# FE310 register map
Vendor: SiFive; Series: Freedom Everywhere; File version: v19p05
E31 CPU Coreplex, high-performance, 32-bit RV32IMAC core
CPU: E31 rv32imac, little endian, no MPU, no FPU, vendor SysTick, 1 interrupt priority bits
Registers are 32-bit, read-write, reset 0x0 unless marked. A register's access mark holds for its fields unless they carry their own. Offsets are from the block's base; lines under a group give offsets from that group; [hi:lo] are bit positions; {n}, {i} and the like mark numbered series; 'fields as' and 'values as' point back to an identical list; <NAME> marks a mode.

## Memory map
0x00020000 OTP_Mem size 0x2000 — One-Time Programmable Memory.
0x02000000 CLINT size 0x10000 — Core Local Interruptor.
0x0C000000 PLIC size 0x200008 — Platform-Level Interrupt Controller.
0x10000000 WDT size 0x40 — Watchdog Timer.
0x10000040 RTC size 0x30 — Real-Time Clock.
0x10000070 AON size 0x10 — AON Clock Configuration.
0x10000080 BACKUP size 0x80 — Backup Registers.
0x10000100 PMU size 0x50 — Power Management Unit.
0x10008000 PRIC size 0x10 — Power, Reset, Clock, Interrupt.
0x10012000 GPIO0 size 0x1000 — General purpose input/output controller.
0x10013000 UART0 size 0x1000 — Universal Asynchronous Receiver/Transmitter.
0x10014000 QSPI0 size 0x1000 — Serial Peripheral Interface.
0x10015000 PWM0 size 0x1000 — Pulse-Width Modulation.
0x10023000 UART1 size 0x1000 — Universal Asynchronous Receiver/Transmitter.
0x10024000 QSPI1 size 0x1000 — Serial Peripheral Interface.
0x10025000 PWM1 size 0x1000
0x10034000 QSPI2 size 0x1000 — Serial Peripheral Interface.
0x10035000 PWM2 size 0x1000

## Interrupts
1 Watchdog_IRQ (WDT)
2 RTC_IRQ (RTC)
3 UART0_IRQ (UART0)
4 UART1_IRQ (UART1)
5 QSPI0_IRQ (QSPI0)
6 QSPI1_IRQ (QSPI1)
7 QSPI2_IRQ (QSPI2)
{n+8} GPIO_{n}_IRQ (GPIO0) (n=0..31)
40 PWMO_CMP0_IRQ (PWM0)
41 PWMO_CMP1_IRQ (PWM0)
42 PWMO_CMP2_IRQ (PWM0)
43 PWMO_CMP3_IRQ (PWM0)
44 PWM1_CMP0_IRQ (PWM1)
45 PWM1_CMP1_IRQ (PWM1)
46 PWM1_CMP2_IRQ (PWM1)
47 PWM1_CMP3_IRQ (PWM1)
48 PWM2_CMP0_IRQ (PWM2)
49 PWM2_CMP1_IRQ (PWM2)
50 PWM2_CMP2_IRQ (PWM2)
51 PWM2_CMP3_IRQ (PWM2)

## OTP_Mem — One-Time Programmable Memory.
Base 0x00020000
0x00 BOOT — Code to jump to LAST FENCE.
0x1FE4 STAMP — Board Identifier.
0x1FE8 LFROSC_TRIM — LFROSC Trim Setting, left unburned on HiFive1.
  [4:0] VALUE
0x1FEC HFROSC_TRIM — HFROSC Trim Setting for 72MHz.
  [4:0] VALUE
0x1FF0 LIFECYCLE — OTP Lifecycle Counter.
{0x1FF4+4i} LAST_FENCE[{i}] (i=0..2) — Code to jump to SPI-FLASH.

## PRIC — Power, Reset, Clock, Interrupt.
Base 0x10008000
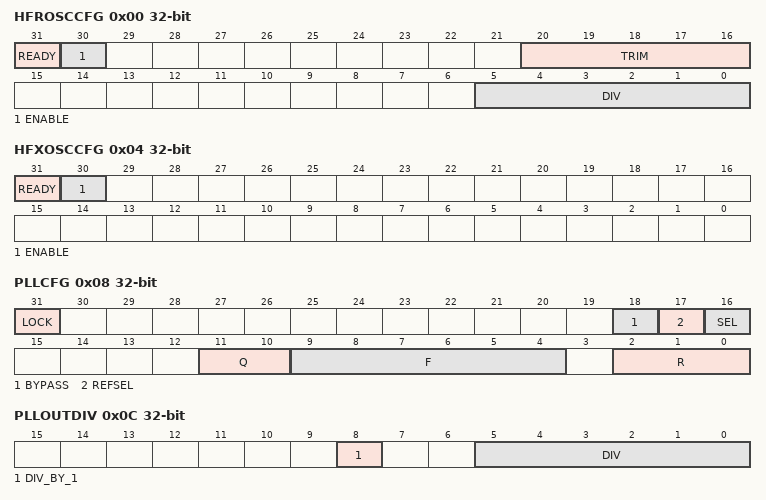
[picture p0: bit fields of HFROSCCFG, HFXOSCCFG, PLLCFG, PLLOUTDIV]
0x00 HFROSCCFG — HF Ring Oscillator Configuration Register.
  [31] READY, [30] ENABLE, [20:16] TRIM, [5:0] DIV
0x04 HFXOSCCFG — HF Crystal Oscillator Configuration Register.
  [31] READY, [30] ENABLE
0x08 PLLCFG — PLL Configuration Register.
  [31] LOCK
  [18] BYPASS
  [17] REFSEL
    1=Crystal OScillator; 0=Internal Oscillator
  [16] SEL
    0=Internal (The HFROSCCLK directly drives HFCLK.); 1=PLL (Drive the final HFCLK with PLL output, bypassed or otherwise.)
  [11:10] Q
  [9:4] F
  [2:0] R
0x0C PLLOUTDIV — PLL Output Divider Register.
  [8] DIV_BY_1, [5:0] DIV

## PLIC — Platform-Level Interrupt Controller.
Base 0x0C000000
{0x0+4i} PRIORITY[{i}] (i=0..51) — PLIC Interrupt Priority Register.
  [2:0] PRIORITY
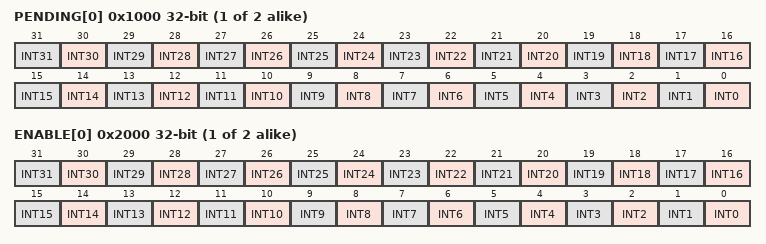
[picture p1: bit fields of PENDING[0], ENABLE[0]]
{0x1000+4i} PENDING[{i}] (i=0..1) — PLIC Interrupt Pending Register.
  [n] INT{n} (n=0..31)
{0x2000+4i} ENABLE[{i}] (i=0..1) — PLIC Interrupt Enable Register.
  [n] INT{n} (n=0..31)
0x200000 THRESHOLD — PLIC Interrupt Priority Threshold Register.
  [2:0] THRESHOLD
0x200004 CLAIM ro — PLIC Claim Register.
0x200004 COMPLETE wo — PLIC Complete Register.

## CLINT — Core Local Interruptor.
Base 0x02000000
0x00 MSIP — Machine Software Interrupt Pending Register.
0x4000 MTIMECMP_LO — Machine Timer Compare Register Low.
0x4004 MTIMECMP_HI — Machine Timer Compare Register High.
0xBFF8 MTIME_LO — Machine Timer Register Low.
0xBFFC MTIME_HI — Machine Timer Register High.
